# MAIN_SEC_MMR_MAIN_SEC_MMR_CFG0_45A00000h register map
Vendor: Texas Instruments
Peripheral module from a debugger description file (folder AM275x).
Registers are 32-bit, read-write, reset 0x0 unless marked. A register's access mark holds for its fields unless they carry their own. Offsets are as the file gives them; lines under a group give offsets from that group; [hi:lo] are bit positions; {n}, {i} and the like mark numbered series; 'fields as' and 'values as' point back to an identical list; <NAME> marks a mode.

## MAIN_SEC_MMR_CFG0
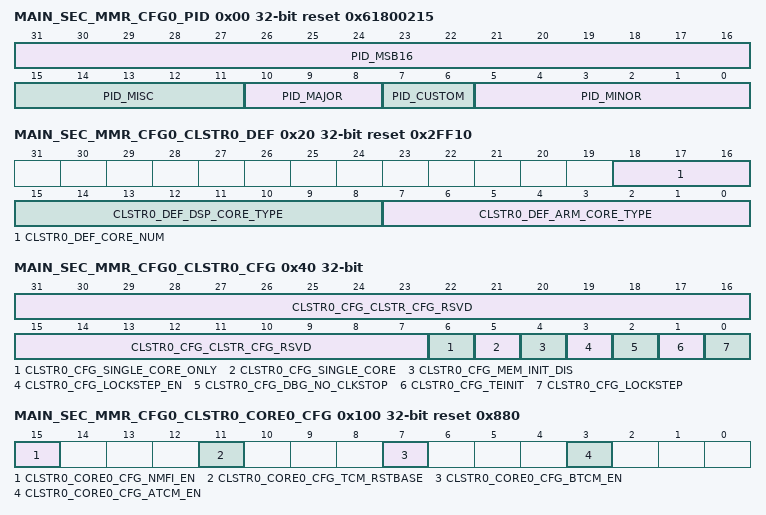
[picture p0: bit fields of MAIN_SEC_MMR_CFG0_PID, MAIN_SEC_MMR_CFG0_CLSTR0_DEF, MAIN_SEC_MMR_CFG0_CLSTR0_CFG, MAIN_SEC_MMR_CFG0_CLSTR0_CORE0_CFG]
0x00 MAIN_SEC_MMR_CFG0_PID ro reset 0x61800215
  [31:16] PID_MSB16 — Reset Source: mod_g_rst_n
  [15:11] PID_MISC — Reset Source: mod_g_rst_n
  [10:8] PID_MAJOR — Reset Source: mod_g_rst_n
  [7:6] PID_CUSTOM — Reset Source: mod_g_rst_n
  [5:0] PID_MINOR — Reset Source: mod_g_rst_n
0x20 MAIN_SEC_MMR_CFG0_CLSTR0_DEF ro reset 0x2FF10 — Defines the type of the processor cluster
  [18:16] CLSTR0_DEF_CORE_NUM — Number of cores in cluster 001 - Single Core 010 - Dual Core 100 - Quad Core Reset Source: mod_g_rst_n
  [15:8] CLSTR0_DEF_DSP_CORE_TYPE — DSP core type configurationField values (others are reserved):8'h00 - C7x8'h01 - C6x8'h10 - AC7x8'hFF - Not DSP Reset Source: mod_g_rst_n
  [7:0] CLSTR0_DEF_ARM_CORE_TYPE — ARM core type configurationField values (others are reserved):8'h00 - A538'h01 - A578'h10 - R58'h11 - M4F8'hFF - Not ARM Reset Source: mod_g_rst_n
0x40 MAIN_SEC_MMR_CFG0_CLSTR0_CFG access per field — Configures cluster level characteristics
  [31:7] CLSTR0_CFG_CLSTR_CFG_RSVD rw — Reserved for future use. Write '0' to ensure compatibility with future devices. Reset Source: sys_por_rst_n
  [6] CLSTR0_CFG_SINGLE_CORE_ONLY ro — Single / Dual Core Custer Support: 0 = Both Dual and Single Core are supported 1 = Only Single Core Mode is Supported Reset Source: sys_por_rst_n
  [5] CLSTR0_CFG_SINGLE_CORE rw — Single / Dual Core Mode: 0 = Both Cores are activate 1 = Only Core0 is active. Reset Source: sys_por_rst_n
  [4] CLSTR0_CFG_MEM_INIT_DIS rw — Disables SRAM initialization (TCM, Cache Tags, etc) at resetInitialization must be performed for proper initial ECC initialization. The mem_init_dis value must be selected prior to R5 reset assertion. 1'b0 - Perform memory initialization 1'b1 - Disable memory initialization Reset Source: mod_g_rst_n
  [3] CLSTR0_CFG_LOCKSTEP_EN ro — Lockstep enable. Indicates if R5 lockstep operation is supported on the device Reset Source: sys_por_rst_n
  [2] CLSTR0_CFG_DBG_NO_CLKSTOP rw — CPU clockstop behavior 0 - CPU clocks stopped and nCLOCKSTOPPED asserted in standby mode 1 - CPU clocks not stopped in standby mode Reset Source: sys_por_rst_n
  [1] CLSTR0_CFG_TEINIT rw — Exception handling state at reset:0 - ARM mode1 - Thumb modeCAUTION: This bit must not be modified if R5F core has been released from reset. Reset Source: sys_por_rst_n
  [0] CLSTR0_CFG_LOCKSTEP rw — When set, Core0 and Core1 operate in lockstep mode. Can only be changed if lockstep operation is supported as indicated by CLSTR0_CFG_lockstep_en = 1. If CLSTR0_CFG_lockstep_en = 0, lockstep is not supported, this bit will be read only with a value of 0. Reset Source: sys_por_rst_n
0x80 MAIN_SEC_MMR_CFG0_CLSTR0_PMCTRL ro — Configures Cluster overall power state
  [31:0] CLSTR0_PMCTRL_RESERVED — Not used for R5F
0x90 MAIN_SEC_MMR_CFG0_CLSTR0_PMSTAT ro — Shows Cluster overall power status
  [31:0] CLSTR0_PMSTAT_RESERVED — Not used for R5F
0x100 MAIN_SEC_MMR_CFG0_CLSTR0_CORE0_CFG reset 0x880 — Configures the TCM and interrupt operation of R5 Core0
  [15] CLSTR0_CORE0_CFG_NMFI_EN — Enable Core0 Non-Maskable Fast InterruptsCAUTION: This bit must not be modified if R5F core has been released from reset. Reset Source: sys_por_rst_n
  [11] CLSTR0_CORE0_CFG_TCM_RSTBASE — Core0 A/BTCM Reset Base Address Indicator 0 - BTCM located at address 0x0 1 - ATCM located at address 0x0CAUTION: This bit must not be modified if R5F core has been released from reset. Reset Source: sys_por_rst_n
  [7] CLSTR0_CORE0_CFG_BTCM_EN — Enable Core0 BTCM RAM at resetCAUTION: This bit must not be modified if R5F core has been released from reset. Reset Source: sys_por_rst_n
  [3] CLSTR0_CORE0_CFG_ATCM_EN — Enable Core0 ATCM RAM at resetCAUTION: This bit must not be modified if R5F core has been released from reset. Reset Source: sys_por_rst_n
0x110 MAIN_SEC_MMR_CFG0_CLSTR0_CORE0_BOOTVECT_LO reset 0x200 — Contains the lower 32 bits of the boot vector location for R5 Core0. Bits 4:0 are not used and are always 0.
  [31:7] CLSTR0_CORE0_BOOTVECT_LO_VECT_ADDR — Specifies the lower 25 bits of the 41-bit vector address corresponding to Vector Table address bits[31:7]. Note bits 6:0 of the Vector Table address are always 0. Reset Source: sys_por_rst_n
0x114 MAIN_SEC_MMR_CFG0_CLSTR0_CORE0_BOOTVECT_HI — Contains the lower 16 bits of the boot vector location for R5 Core0
  [15:0] CLSTR0_CORE0_BOOTVECT_HI_VECT_ADDR — Specifies the upper 16 bits of the 41-bit vector address corresponding to Vector Table address bits[47:32]. Reset Source: sys_por_rst_n
0x120 MAIN_SEC_MMR_CFG0_CLSTR0_CORE0_PMCTRL — Configures Cluster Core0 power state
  [0] CLSTR0_CORE0_PMCTRL_CORE_HALT — Halt Core0Field values (others are reserved):1'b0 - Core0 is held waiting to begin execution after reset1'b1 - Core0 is released for execution after reset Reset Source: sys_por_rst_n
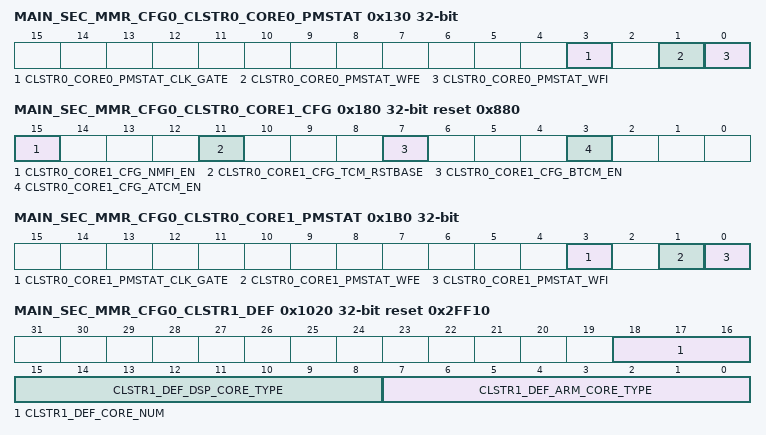
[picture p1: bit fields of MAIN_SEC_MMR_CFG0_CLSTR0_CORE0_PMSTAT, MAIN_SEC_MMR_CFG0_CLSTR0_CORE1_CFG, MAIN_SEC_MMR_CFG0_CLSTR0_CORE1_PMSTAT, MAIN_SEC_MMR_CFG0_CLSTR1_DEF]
0x130 MAIN_SEC_MMR_CFG0_CLSTR0_CORE0_PMSTAT ro — Shows Cluster Core0 power status
  [3] CLSTR0_CORE0_PMSTAT_CLK_GATE — Core0 Clocked stopped due to WFI or WFE stateNote: Bit value is invalid when Core0 is in reset Reset Source: mod_g_rst_n
  [1] CLSTR0_CORE0_PMSTAT_WFE — Core0 WFEWhen 0, indicates that Core0 is in the WFE stateNote: Bit value is invalid when Core0 is in reset Reset Source: mod_g_rst_n
  [0] CLSTR0_CORE0_PMSTAT_WFI — Core0 WFIWhen 0, indicates that Core0 is in the WFI stateNote: Bit value is invalid when Core0 is in reset Reset Source: mod_g_rst_n
0x180 MAIN_SEC_MMR_CFG0_CLSTR0_CORE1_CFG reset 0x880 — Configures the TCM and interrupt operation of R5 Core1
  [15] CLSTR0_CORE1_CFG_NMFI_EN — Enable Core1 Non-Maskable Fast InterruptsCAUTION: This bit must not be modified if R5F core has been released from reset. Reset Source: sys_por_rst_n
  [11] CLSTR0_CORE1_CFG_TCM_RSTBASE — Core1 A/BTCM Reset Base Address Indicator 0 - BTCM located at address 0x0 1 - ATCM located at address 0x0CAUTION: This bit must not be modified if R5F core has been released from reset. Reset Source: sys_por_rst_n
  [7] CLSTR0_CORE1_CFG_BTCM_EN — Enable Core1 BTCM RAM at resetCAUTION: This bit must not be modified if R5F core has been released from reset. Reset Source: sys_por_rst_n
  [3] CLSTR0_CORE1_CFG_ATCM_EN — Enable Core1 ATCM RAM at resetCAUTION: This bit must not be modified if R5F core has been released from reset. Reset Source: sys_por_rst_n
0x190 MAIN_SEC_MMR_CFG0_CLSTR0_CORE1_BOOTVECT_LO reset 0x200 — Contains the lower 32 bits of the boot vector location for R5 Core1. Bits 4:0 are not used and are always 0.
  [31:7] CLSTR0_CORE1_BOOTVECT_LO_VECT_ADDR — Specifies the lower 25 bits of the 41-bit vector address corresponding to Vector Table address bits[31:7]. Note bits 6:0 of the Vector Table address are always 0. Reset Source: sys_por_rst_n
0x194 MAIN_SEC_MMR_CFG0_CLSTR0_CORE1_BOOTVECT_HI — Contains the lower 16 bits of the boot vector location for R5 Core1
  [15:0] CLSTR0_CORE1_BOOTVECT_HI_VECT_ADDR — Specifies the upper 16 bits of the 41-bit vector address corresponding to Vector Table address bits[47:32]. Reset Source: sys_por_rst_n
0x1A0 MAIN_SEC_MMR_CFG0_CLSTR0_CORE1_PMCTRL — Configures Cluster Core1 power state
  [0] CLSTR0_CORE1_PMCTRL_CORE_HALT — Halt Core1Field values (others are reserved):1'b0 - Core1 is held waiting to begin execution after reset1'b1 - Core1 is released for execution after reset Reset Source: sys_por_rst_n
0x1B0 MAIN_SEC_MMR_CFG0_CLSTR0_CORE1_PMSTAT ro — Shows Cluster Core1 power status
  [3] CLSTR0_CORE1_PMSTAT_CLK_GATE — Core1 Clocked stopped due to WFI or WFE stateNote: Bit value is invalid when Core1 is in reset Reset Source: mod_g_rst_n
  [1] CLSTR0_CORE1_PMSTAT_WFE — Core1 WFEWhen 0, indicates that Core1 is in the WFE stateNote: Bit value is invalid when Core1 is in reset Reset Source: mod_g_rst_n
  [0] CLSTR0_CORE1_PMSTAT_WFI — Core1 WFIWhen 0, indicates that Core1 is in the WFI stateNote: Bit value is invalid when Core1 is in reset Reset Source: mod_g_rst_n
0x1020 MAIN_SEC_MMR_CFG0_CLSTR1_DEF ro reset 0x2FF10 — Defines the type of the processor cluster
  [18:16] CLSTR1_DEF_CORE_NUM — Number of cores in cluster 001 - Single Core 010 - Dual Core 100 - Quad Core Reset Source: mod_g_rst_n
  [15:8] CLSTR1_DEF_DSP_CORE_TYPE — DSP core type configurationField values (others are reserved):8'h00 - C7x8'h01 - C6x8'h10 - AC7x8'hFF - Not DSP Reset Source: mod_g_rst_n
  [7:0] CLSTR1_DEF_ARM_CORE_TYPE — ARM core type configurationField values (others are reserved):8'h00 - A538'h01 - A578'h10 - R58'h11 - M4F8'hFF - Not ARM Reset Source: mod_g_rst_n
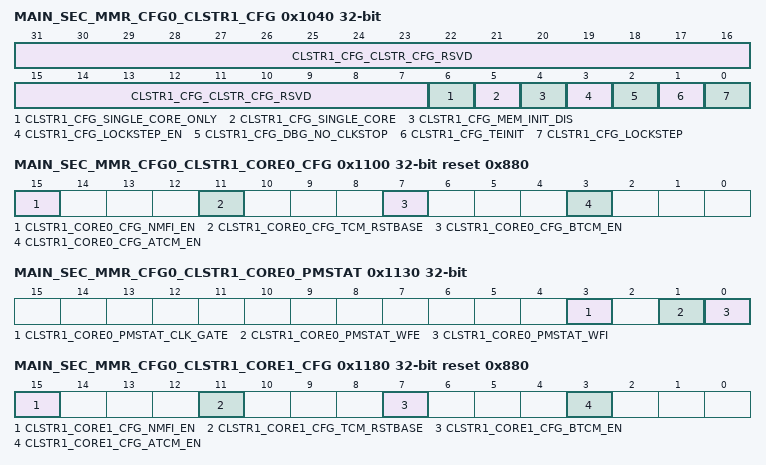
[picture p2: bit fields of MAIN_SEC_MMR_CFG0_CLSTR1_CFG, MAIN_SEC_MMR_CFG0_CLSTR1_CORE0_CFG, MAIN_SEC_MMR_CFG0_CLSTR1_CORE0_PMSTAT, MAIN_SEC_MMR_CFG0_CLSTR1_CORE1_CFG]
0x1040 MAIN_SEC_MMR_CFG0_CLSTR1_CFG access per field — Configures cluster level characteristics
  [31:7] CLSTR1_CFG_CLSTR_CFG_RSVD rw — Reserved for future use. Write '0' to ensure compatibility with future devices. Reset Source: sys_por_rst_n
  [6] CLSTR1_CFG_SINGLE_CORE_ONLY ro — Single / Dual Core Custer Support: 0 = Both Dual and Single Core are supported 1 = Only Single Core Mode is Supported Reset Source: sys_por_rst_n
  [5] CLSTR1_CFG_SINGLE_CORE rw — Single / Dual Core Mode: 0 = Both Cores are activate 1 = Only Core0 is active. Reset Source: sys_por_rst_n
  [4] CLSTR1_CFG_MEM_INIT_DIS rw — Disables SRAM initialization (TCM, Cache Tags, etc) at resetInitialization must be performed for proper initial ECC initialization. The mem_init_dis value must be selected prior to R5 reset assertion. 1'b0 - Perform memory initialization 1'b1 - Disable memory initialization Reset Source: mod_g_rst_n
  [3] CLSTR1_CFG_LOCKSTEP_EN ro — Lockstep enable. Indicates if R5 lockstep operation is supported on the device Reset Source: sys_por_rst_n
  [2] CLSTR1_CFG_DBG_NO_CLKSTOP rw — CPU clockstop behavior 0 - CPU clocks stopped and nCLOCKSTOPPED asserted in standby mode 1 - CPU clocks not stopped in standby mode Reset Source: sys_por_rst_n
  [1] CLSTR1_CFG_TEINIT rw — Exception handling state at reset:0 - ARM mode1 - Thumb modeCAUTION: This bit must not be modified if R5F core has been released from reset. Reset Source: sys_por_rst_n
  [0] CLSTR1_CFG_LOCKSTEP rw — When set, Core0 and Core1 operate in lockstep mode. Can only be changed if lockstep operation is supported as indicated by CLSTR1_CFG_lockstep_en = 1. If CLSTR1_CFG_lockstep_en = 0, lockstep is not supported, this bit will be read only with a value of 0. Reset Source: sys_por_rst_n
0x1080 MAIN_SEC_MMR_CFG0_CLSTR1_PMCTRL ro — Configures Cluster overall power state
  [31:0] CLSTR1_PMCTRL_RESERVED — Not used for R5F
0x1090 MAIN_SEC_MMR_CFG0_CLSTR1_PMSTAT ro — Shows Cluster overall power status
  [31:0] CLSTR1_PMSTAT_RESERVED — Not used for R5F
0x1100 MAIN_SEC_MMR_CFG0_CLSTR1_CORE0_CFG reset 0x880 — Configures the TCM and interrupt operation of R5 Core0
  [15] CLSTR1_CORE0_CFG_NMFI_EN — Enable Core0 Non-Maskable Fast InterruptsCAUTION: This bit must not be modified if R5F core has been released from reset. Reset Source: sys_por_rst_n
  [11] CLSTR1_CORE0_CFG_TCM_RSTBASE — Core0 A/BTCM Reset Base Address Indicator 0 - BTCM located at address 0x0 1 - ATCM located at address 0x0CAUTION: This bit must not be modified if R5F core has been released from reset. Reset Source: sys_por_rst_n
  [7] CLSTR1_CORE0_CFG_BTCM_EN — Enable Core0 BTCM RAM at resetCAUTION: This bit must not be modified if R5F core has been released from reset. Reset Source: sys_por_rst_n
  [3] CLSTR1_CORE0_CFG_ATCM_EN — Enable Core0 ATCM RAM at resetCAUTION: This bit must not be modified if R5F core has been released from reset. Reset Source: sys_por_rst_n
0x1110 MAIN_SEC_MMR_CFG0_CLSTR1_CORE0_BOOTVECT_LO reset 0x200 — Contains the lower 32 bits of the boot vector location for R5 Core0. Bits 4:0 are not used and are always 0.
  [31:7] CLSTR1_CORE0_BOOTVECT_LO_VECT_ADDR — Specifies the lower 25 bits of the 41-bit vector address corresponding to Vector Table address bits[31:7]. Note bits 6:0 of the Vector Table address are always 0. Reset Source: sys_por_rst_n
0x1114 MAIN_SEC_MMR_CFG0_CLSTR1_CORE0_BOOTVECT_HI — Contains the lower 16 bits of the boot vector location for R5 Core0
  [15:0] CLSTR1_CORE0_BOOTVECT_HI_VECT_ADDR — Specifies the upper 16 bits of the 41-bit vector address corresponding to Vector Table address bits[47:32]. Reset Source: sys_por_rst_n
0x1120 MAIN_SEC_MMR_CFG0_CLSTR1_CORE0_PMCTRL — Configures Cluster Core0 power state
  [0] CLSTR1_CORE0_PMCTRL_CORE_HALT — Halt Core0Field values (others are reserved):1'b0 - Core0 is held waiting to begin execution after reset1'b1 - Core0 is released for execution after reset Reset Source: sys_por_rst_n
0x1130 MAIN_SEC_MMR_CFG0_CLSTR1_CORE0_PMSTAT ro — Shows Cluster Core0 power status
  [3] CLSTR1_CORE0_PMSTAT_CLK_GATE — Core0 Clocked stopped due to WFI or WFE stateNote: Bit value is invalid when Core0 is in reset Reset Source: mod_g_rst_n
  [1] CLSTR1_CORE0_PMSTAT_WFE — Core0 WFEWhen 0, indicates that Core0 is in the WFE stateNote: Bit value is invalid when Core0 is in reset Reset Source: mod_g_rst_n
  [0] CLSTR1_CORE0_PMSTAT_WFI — Core0 WFIWhen 0, indicates that Core0 is in the WFI stateNote: Bit value is invalid when Core0 is in reset Reset Source: mod_g_rst_n
0x1180 MAIN_SEC_MMR_CFG0_CLSTR1_CORE1_CFG reset 0x880 — Configures the TCM and interrupt operation of R5 Core1
  [15] CLSTR1_CORE1_CFG_NMFI_EN — Enable Core1 Non-Maskable Fast InterruptsCAUTION: This bit must not be modified if R5F core has been released from reset. Reset Source: sys_por_rst_n
  [11] CLSTR1_CORE1_CFG_TCM_RSTBASE — Core1 A/BTCM Reset Base Address Indicator 0 - BTCM located at address 0x0 1 - ATCM located at address 0x0CAUTION: This bit must not be modified if R5F core has been released from reset. Reset Source: sys_por_rst_n
  [7] CLSTR1_CORE1_CFG_BTCM_EN — Enable Core1 BTCM RAM at resetCAUTION: This bit must not be modified if R5F core has been released from reset. Reset Source: sys_por_rst_n
  [3] CLSTR1_CORE1_CFG_ATCM_EN — Enable Core1 ATCM RAM at resetCAUTION: This bit must not be modified if R5F core has been released from reset. Reset Source: sys_por_rst_n
0x1190 MAIN_SEC_MMR_CFG0_CLSTR1_CORE1_BOOTVECT_LO reset 0x200 — Contains the lower 32 bits of the boot vector location for R5 Core1. Bits 4:0 are not used and are always 0.
  [31:7] CLSTR1_CORE1_BOOTVECT_LO_VECT_ADDR — Specifies the lower 25 bits of the 41-bit vector address corresponding to Vector Table address bits[31:7]. Note bits 6:0 of the Vector Table address are always 0. Reset Source: sys_por_rst_n
0x1194 MAIN_SEC_MMR_CFG0_CLSTR1_CORE1_BOOTVECT_HI — Contains the lower 16 bits of the boot vector location for R5 Core1
  [15:0] CLSTR1_CORE1_BOOTVECT_HI_VECT_ADDR — Specifies the upper 16 bits of the 41-bit vector address corresponding to Vector Table address bits[47:32]. Reset Source: sys_por_rst_n
0x11A0 MAIN_SEC_MMR_CFG0_CLSTR1_CORE1_PMCTRL — Configures Cluster Core1 power state
  [0] CLSTR1_CORE1_PMCTRL_CORE_HALT — Halt Core1Field values (others are reserved):1'b0 - Core1 is held waiting to begin execution after reset1'b1 - Core1 is released for execution after reset Reset Source: sys_por_rst_n
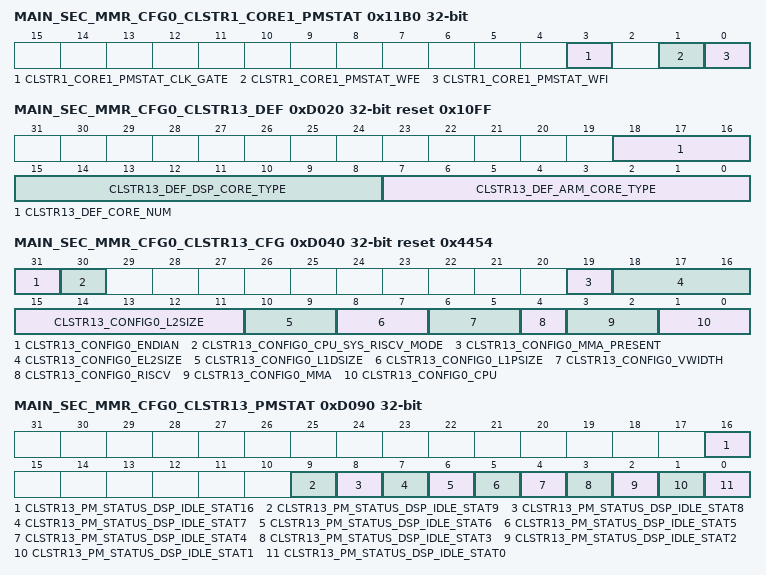
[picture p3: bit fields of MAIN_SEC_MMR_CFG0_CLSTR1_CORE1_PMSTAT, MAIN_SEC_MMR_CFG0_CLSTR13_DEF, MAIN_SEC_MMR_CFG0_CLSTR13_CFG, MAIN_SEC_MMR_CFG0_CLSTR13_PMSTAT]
0x11B0 MAIN_SEC_MMR_CFG0_CLSTR1_CORE1_PMSTAT ro — Shows Cluster Core1 power status
  [3] CLSTR1_CORE1_PMSTAT_CLK_GATE — Core1 Clocked stopped due to WFI or WFE stateNote: Bit value is invalid when Core1 is in reset Reset Source: mod_g_rst_n
  [1] CLSTR1_CORE1_PMSTAT_WFE — Core1 WFEWhen 0, indicates that Core1 is in the WFE stateNote: Bit value is invalid when Core1 is in reset Reset Source: mod_g_rst_n
  [0] CLSTR1_CORE1_PMSTAT_WFI — Core1 WFIWhen 0, indicates that Core1 is in the WFI stateNote: Bit value is invalid when Core1 is in reset Reset Source: mod_g_rst_n
0xD020 MAIN_SEC_MMR_CFG0_CLSTR13_DEF ro reset 0x10FF — Defines the type of the processor cluster
  [18:16] CLSTR13_DEF_CORE_NUM — Number of cores in cluster 000 - Single Core 001 - Dual Core 010 - Quad Core Reset Source: mod_g_rst_n
  [15:8] CLSTR13_DEF_DSP_CORE_TYPE — DSP core type configurationField values (others are reserved):8'h00 - C7x8'h01 - C6x8'h10 - AC7x8'hFF - Not DSP Reset Source: mod_g_rst_n
  [7:0] CLSTR13_DEF_ARM_CORE_TYPE — ARM core type configurationField values (others are reserved):8'h00 - A538'h01 - A578'h10 - R58'h11 - M4F8'hFF - Not ARM Reset Source: mod_g_rst_n
0xD040 MAIN_SEC_MMR_CFG0_CLSTR13_CFG access per field reset 0x4454 — Configures cluster level characteristics
  [31] CLSTR13_CONFIG0_ENDIAN rw — Reset value of Endian control. 0 - Little Endian1 - Big Endian Reset Source: mod_g_rst_n
  [30] CLSTR13_CONFIG0_CPU_SYS_RISCV_MODE rw — Activates CPU Booting in RiscV Mode0 - Boot in C7x ISA Mode1 - Boot in RiscV ISA Mode Reset Source: mod_g_rst_n
  [19] CLSTR13_CONFIG0_MMA_PRESENT rw — MMA is present. This bit is intended to be read not modified and writes to this bit will not have any impact on the C7xv mma presence which is directly controlled by efuse. Reset Source: mod_g_rst_n
  [18:16] CLSTR13_CONFIG0_EL2SIZE ro — EL2 SizeField values (others are reserved):3'b000 - None3'b001 - 1 MB3'b010 - 1.5 MB3'b011 - 2 MB3'b100 - 2.5 MB3'b101 - 3 MB3'b110 - 3.5MB3'b111 - 4 Mb Reset Source: mod_g_rst_n
  [15:11] CLSTR13_CONFIG0_L2SIZE ro — L2 SizeField values (others are reserved):5'b00000 - None5'b00001 - 512 KB5'b00010 - 768 KB5'b00011 - 1 MB5'b00100 - 1.25 MB5'b00101 - 1.5 MB5'b00110 - 1.75 MB5'b00111 - 2 MB5'b01000 - 2.25 MB5'b01001 - 2.5 MB5'b01010 - 2.75 MB5'b01011 - 3 MB5'b00100 - 3.25 MB5'b01101 - 3.5 MB5'b01110 - 3.75 MB5'b01111 - 4 MB5'b10000 - 4.5 MB5'b10001 - 5 MB5'b10010 - 5.5 MB5'b10011 - 6 MB5'b10100 - 6.5 MB5'b10101 - 7 MB5'b10110 - 7.5 MB5'b10111 - 8 MB Reset Source: mod_g_rst_n
  [10:9] CLSTR13_CONFIG0_L1DSIZE ro — L1D Cache SizeField values (others are reserved):2'b00 - 32 KB2'b01 - 48 KB2'b10 - 64 KB2'b11 - 128 KB Reset Source: mod_g_rst_n
  [8:7] CLSTR13_CONFIG0_L1PSIZE ro — L1P Cache SizeField values (others are reserved):2'b00 - 32 KB2'b01 - 48 KB2'b10 - 64 KB2'b11 - 128 KB Reset Source: mod_g_rst_n
  [6:5] CLSTR13_CONFIG0_VWIDTH ro — Vector WidthField values (others are reserved):2'b00 - 64 bit2'b01 - 128 bit2'b10 - 256 bit2'b11 - 512 bit Reset Source: mod_g_rst_n
  [4] CLSTR13_CONFIG0_RISCV ro — RISCV ISA SupportField values (others are reserved):1'b0 - Not Supported1'b1 - Supported Reset Source: mod_g_rst_n
  [3:2] CLSTR13_CONFIG0_MMA ro — MMA TypeField values (others are reserved):2'b00 - Reserved2'b01 - Reserved2'b10 - MMA22'b11 - MMA2p1 Reset Source: mod_g_rst_n
  [1:0] CLSTR13_CONFIG0_CPU ro — CPU TypeField values (others are reserved):2'b00 - Reserved2'b01 - Reserved2'b10 - Reserved2'b11 - AC72 R10 Reset Source: mod_g_rst_n
0xD090 MAIN_SEC_MMR_CFG0_CLSTR13_PMSTAT ro — Contains Idle Status for C7x DSP Cluster
  [16] CLSTR13_PM_STATUS_DSP_IDLE_STAT16 — C7x PBIST Idle StatusField values (others are reserved):1'b0 - Idle1'b1 - Not Idle Reset Source: mod_g_rst_n
  [9] CLSTR13_PM_STATUS_DSP_IDLE_STAT9 — ReservedField values (others are reserved):1'b0 - Idle1'b1 - Not Idle Reset Source: mod_g_rst_n
  [8] CLSTR13_PM_STATUS_DSP_IDLE_STAT8 — C7x DRU Idle StatusField values (others are reserved):1'b0 - Idle1'b1 - Not Idle Reset Source: mod_g_rst_n
  [7] CLSTR13_PM_STATUS_DSP_IDLE_STAT7 — C7x L2 Idle StatusField values (others are reserved):1'b0 - Idle1'b1 - Not Idle Reset Source: mod_g_rst_n
  [6] CLSTR13_PM_STATUS_DSP_IDLE_STAT6 — C7x Debug Idle StatusField values (others are reserved):1'b0 - Idle1'b1 - Not Idle Reset Source: mod_g_rst_n
  [5] CLSTR13_PM_STATUS_DSP_IDLE_STAT5 — C7x SE Idle StatusField values (others are reserved):1'b0 - Idle1'b1 - Not Idle Reset Source: mod_g_rst_n
  [4] CLSTR13_PM_STATUS_DSP_IDLE_STAT4 — C7x DMC Idle StatusField values (others are reserved):1'b0 - Idle1'b1 - Not Idle Reset Source: mod_g_rst_n
  [3] CLSTR13_PM_STATUS_DSP_IDLE_STAT3 — C7x PMC Idle StatusField values (others are reserved):1'b0 - Idle1'b1 - Not Idle Reset Source: mod_g_rst_n
  [2] CLSTR13_PM_STATUS_DSP_IDLE_STAT2 — C7x CPU Idle StatusField values (others are reserved):1'b0 - Idle1'b1 - Not Idle Reset Source: mod_g_rst_n
  [1] CLSTR13_PM_STATUS_DSP_IDLE_STAT1 — C7x Core LPSC Idle StatusField values (others are reserved):1'b0 - Idle1'b1 - Not Idle Reset Source: mod_g_rst_n
  [0] CLSTR13_PM_STATUS_DSP_IDLE_STAT0 — Composite Idle StatusField values (others are reserved):1'b0 - Idle1'b1 - Not Idle Reset Source: mod_g_rst_n
0xD110 MAIN_SEC_MMR_CFG0_CLSTR13_CORE0_BOOTVECT_LO — Contains Bits [33:2] of the Boot Vector for C7x DSP
  [31:0] CLSTR13_RST_VEC_LO_CORE0_RESET_BASE_VECTOR_LO — Reset Vector Base Address 33:2 for C7x Reset Source: mod_g_rst_n
0xD114 MAIN_SEC_MMR_CFG0_CLSTR13_CORE0_BOOTVECT_HI — Contains Bits [35:34] of the Boot Vector for C7x DSP
  [1:0] CLSTR13_RST_VEC_HI_CORE0_RESET_BASE_VECTOR_HI — Reset Vector Base Address 35:34 for C7x Reset Source: mod_g_rst_n
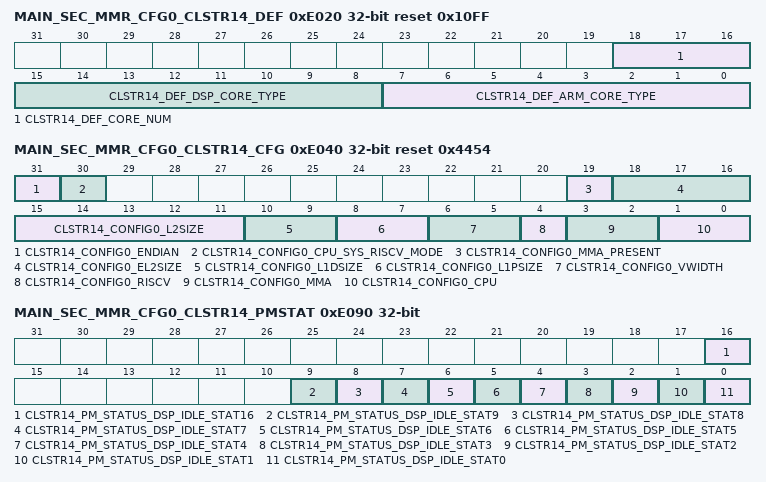
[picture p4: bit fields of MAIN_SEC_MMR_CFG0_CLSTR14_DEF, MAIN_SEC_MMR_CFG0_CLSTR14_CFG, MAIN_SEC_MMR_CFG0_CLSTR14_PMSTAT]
0xE020 MAIN_SEC_MMR_CFG0_CLSTR14_DEF ro reset 0x10FF — Defines the type of the processor cluster
  [18:16] CLSTR14_DEF_CORE_NUM — Number of cores in cluster 000 - Single Core 001 - Dual Core 010 - Quad Core Reset Source: mod_g_rst_n
  [15:8] CLSTR14_DEF_DSP_CORE_TYPE — DSP core type configurationField values (others are reserved):8'h00 - C7x8'h01 - C6x8'h10 - AC7x8'hFF - Not DSP Reset Source: mod_g_rst_n
  [7:0] CLSTR14_DEF_ARM_CORE_TYPE — ARM core type configurationField values (others are reserved):8'h00 - A538'h01 - A578'h10 - R58'h11 - M4F8'hFF - Not ARM Reset Source: mod_g_rst_n
0xE040 MAIN_SEC_MMR_CFG0_CLSTR14_CFG access per field reset 0x4454 — Configures cluster level characteristics
  [31] CLSTR14_CONFIG0_ENDIAN rw — Reset value of Endian control. 0 - Little Endian1 - Big Endian Reset Source: mod_g_rst_n
  [30] CLSTR14_CONFIG0_CPU_SYS_RISCV_MODE rw — Activates CPU Booting in RiscV Mode0 - Boot in C7x ISA Mode1 - Boot in RiscV ISA Mode Reset Source: mod_g_rst_n
  [19] CLSTR14_CONFIG0_MMA_PRESENT rw — MMA is present. This bit is intended to be read not modified and writes to this bit will not have any impact on the C7xv mma presence which is directly controlled by efuse. Reset Source: mod_g_rst_n
  [18:16] CLSTR14_CONFIG0_EL2SIZE ro — EL2 SizeField values (others are reserved):3'b000 - None3'b001 - 1 MB3'b010 - 1.5 MB3'b011 - 2 MB3'b100 - 2.5 MB3'b101 - 3 MB3'b110 - 3.5MB3'b111 - 4 Mb Reset Source: mod_g_rst_n
  [15:11] CLSTR14_CONFIG0_L2SIZE ro — L2 SizeField values (others are reserved):5'b00000 - None5'b00001 - 512 KB5'b00010 - 768 KB5'b00011 - 1 MB5'b00100 - 1.25 MB5'b00101 - 1.5 MB5'b00110 - 1.75 MB5'b00111 - 2 MB5'b01000 - 2.25 MB5'b01001 - 2.5 MB5'b01010 - 2.75 MB5'b01011 - 3 MB5'b00100 - 3.25 MB5'b01101 - 3.5 MB5'b01110 - 3.75 MB5'b01111 - 4 MB5'b10000 - 4.5 MB5'b10001 - 5 MB5'b10010 - 5.5 MB5'b10011 - 6 MB5'b10100 - 6.5 MB5'b10101 - 7 MB5'b10110 - 7.5 MB5'b10111 - 8 MB Reset Source: mod_g_rst_n
  [10:9] CLSTR14_CONFIG0_L1DSIZE ro — L1D Cache SizeField values (others are reserved):2'b00 - 32 KB2'b01 - 48 KB2'b10 - 64 KB2'b11 - 128 KB Reset Source: mod_g_rst_n
  [8:7] CLSTR14_CONFIG0_L1PSIZE ro — L1P Cache SizeField values (others are reserved):2'b00 - 32 KB2'b01 - 48 KB2'b10 - 64 KB2'b11 - 128 KB Reset Source: mod_g_rst_n
  [6:5] CLSTR14_CONFIG0_VWIDTH ro — Vector WidthField values (others are reserved):2'b00 - 64 bit2'b01 - 128 bit2'b10 - 256 bit2'b11 - 512 bit Reset Source: mod_g_rst_n
  [4] CLSTR14_CONFIG0_RISCV ro — RISCV ISA SupportField values (others are reserved):1'b0 - Not Supported1'b1 - Supported Reset Source: mod_g_rst_n
  [3:2] CLSTR14_CONFIG0_MMA ro — MMA TypeField values (others are reserved):2'b00 - Reserved2'b01 - Reserved2'b10 - MMA22'b11 - MMA2p1 Reset Source: mod_g_rst_n
  [1:0] CLSTR14_CONFIG0_CPU ro — CPU TypeField values (others are reserved):2'b00 - Reserved2'b01 - Reserved2'b10 - Reserved2'b11 - AC72 R10 Reset Source: mod_g_rst_n
0xE090 MAIN_SEC_MMR_CFG0_CLSTR14_PMSTAT ro — Contains Idle Status for C7x DSP Cluster
  [16] CLSTR14_PM_STATUS_DSP_IDLE_STAT16 — C7x PBIST Idle StatusField values (others are reserved):1'b0 - Idle1'b1 - Not Idle Reset Source: mod_g_rst_n
  [9] CLSTR14_PM_STATUS_DSP_IDLE_STAT9 — ReservedField values (others are reserved):1'b0 - Idle1'b1 - Not Idle Reset Source: mod_g_rst_n
  [8] CLSTR14_PM_STATUS_DSP_IDLE_STAT8 — C7x DRU Idle StatusField values (others are reserved):1'b0 - Idle1'b1 - Not Idle Reset Source: mod_g_rst_n
  [7] CLSTR14_PM_STATUS_DSP_IDLE_STAT7 — C7x L2 Idle StatusField values (others are reserved):1'b0 - Idle1'b1 - Not Idle Reset Source: mod_g_rst_n
  [6] CLSTR14_PM_STATUS_DSP_IDLE_STAT6 — C7x Debug Idle StatusField values (others are reserved):1'b0 - Idle1'b1 - Not Idle Reset Source: mod_g_rst_n
  [5] CLSTR14_PM_STATUS_DSP_IDLE_STAT5 — C7x SE Idle StatusField values (others are reserved):1'b0 - Idle1'b1 - Not Idle Reset Source: mod_g_rst_n
  [4] CLSTR14_PM_STATUS_DSP_IDLE_STAT4 — C7x DMC Idle StatusField values (others are reserved):1'b0 - Idle1'b1 - Not Idle Reset Source: mod_g_rst_n
  [3] CLSTR14_PM_STATUS_DSP_IDLE_STAT3 — C7x PMC Idle StatusField values (others are reserved):1'b0 - Idle1'b1 - Not Idle Reset Source: mod_g_rst_n
  [2] CLSTR14_PM_STATUS_DSP_IDLE_STAT2 — C7x CPU Idle StatusField values (others are reserved):1'b0 - Idle1'b1 - Not Idle Reset Source: mod_g_rst_n
  [1] CLSTR14_PM_STATUS_DSP_IDLE_STAT1 — C7x Core LPSC Idle StatusField values (others are reserved):1'b0 - Idle1'b1 - Not Idle Reset Source: mod_g_rst_n
  [0] CLSTR14_PM_STATUS_DSP_IDLE_STAT0 — Composite Idle StatusField values (others are reserved):1'b0 - Idle1'b1 - Not Idle Reset Source: mod_g_rst_n
0xE110 MAIN_SEC_MMR_CFG0_CLSTR14_CORE0_BOOTVECT_LO — Contains Bits [33:2] of the Boot Vector for C7x DSP
  [31:0] CLSTR14_RST_VEC_LO_CORE0_RESET_BASE_VECTOR_LO — Reset Vector Base Address 33:2 for C7x Reset Source: mod_g_rst_n
0xE114 MAIN_SEC_MMR_CFG0_CLSTR14_CORE0_BOOTVECT_HI — Contains Bits [35:34] of the Boot Vector for C7x DSP
  [1:0] CLSTR14_RST_VEC_HI_CORE0_RESET_BASE_VECTOR_HI — Reset Vector Base Address 35:34 for C7x Reset Source: mod_g_rst_n
